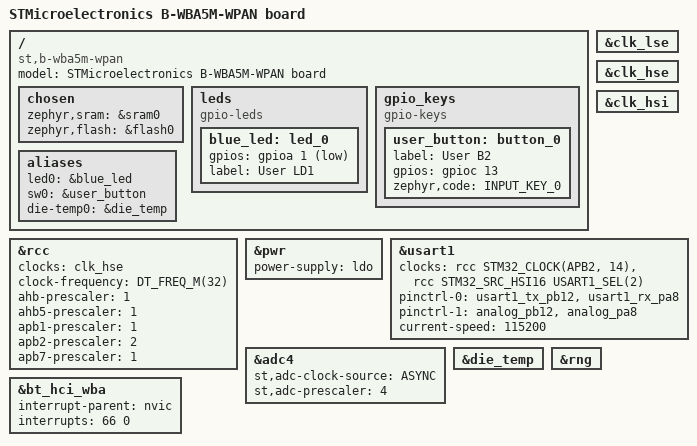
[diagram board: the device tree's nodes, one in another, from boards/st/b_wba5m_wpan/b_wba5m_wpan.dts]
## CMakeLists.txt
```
cmake_minimum_required(VERSION 3.20.0)

# App-lokale Board-Definitionen (boards/st/...) auffindbar machen
list(APPEND BOARD_ROOT ${CMAKE_CURRENT_SOURCE_DIR})

find_package(Zephyr REQUIRED HINTS $ENV{ZEPHYR_BASE})
project(ble_serial_bridge)

target_sources(app PRIVATE src/main.c)
```

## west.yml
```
# West-Manifest: pinnt Zephyr auf v4.4.2 (passend zum Zephyr SDK 1.0.x).
#
# Verwendung (T2-Topologie, diese Repo ist das Manifest-Repository):
#   west init -l <pfad-zu-diesem-repo>
#   west update
manifest:
  self:
    path: bleserial

  remotes:
    - name: zephyrproject-rtos
      url-base: https://github.com/zephyrproject-rtos

  projects:
    - name: zephyr
      remote: zephyrproject-rtos
      revision: v4.4.2
      import:
        # Nur die Module holen, die fuer STM32WB gebraucht werden
        # (mbedtls + tf-psa-crypto: PSA-Crypto fuer den Bluetooth-Host)
        name-allowlist:
          - cmsis
          - cmsis_6
          - hal_stm32
          - mbedtls
          - tf-psa-crypto
```

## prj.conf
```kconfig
# Bluetooth LE Peripheral mit Zephyr-NUS-Service (Nordic UART Service UUIDs)
CONFIG_BT=y
CONFIG_BT_PERIPHERAL=y
CONFIG_BT_MAX_CONN=1
CONFIG_BT_DEVICE_NAME="BLESerial-WB5MM"
CONFIG_BT_ZEPHYR_NUS=y

# Groessere ATT-MTU zulassen (Central muss sie aushandeln):
# 247 Byte MTU => 244 Byte Nutzdaten pro Notification
CONFIG_BT_L2CAP_TX_MTU=247
CONFIG_BT_BUF_ACL_TX_SIZE=251
CONFIG_BT_BUF_ACL_RX_SIZE=251

# Bridge-UART (LPUART1, interruptgesteuert mit Ringpuffern)
CONFIG_SERIAL=y
CONFIG_UART_INTERRUPT_DRIVEN=y
CONFIG_RING_BUFFER=y

# Status-/Diagnoseausgaben auf der ST-LINK-VCP-Konsole (USART1)
CONFIG_LOG=y
CONFIG_LOG_DEFAULT_LEVEL=3
```

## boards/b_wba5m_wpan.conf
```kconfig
# Kein Konsolen-UART auf diesem Board: USART1 gehoert der Bridge,
# daher Logging deaktivieren.
CONFIG_LOG=n
```

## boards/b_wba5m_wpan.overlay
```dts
/*
 * B-WBA5M-WPAN: USART1 als Bridge-UART verwenden.
 *
 * USART1 (PB12 = TX, PA8 = RX) ist der Host-UART der M.2-E-Key-Karte
 * (BSP "COM1") - die Karte verhaelt sich damit als transparentes
 * BLE-Serial-Modem fuer das Host-Board.
 */

/ {
	aliases {
		bridge-uart = &usart1;
	};
};

&usart1 {
	status = "okay";
	current-speed = <115200>;
};
```

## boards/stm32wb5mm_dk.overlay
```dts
/*
 * STM32WB5MM-DK: LPUART1 als Bridge-UART verwenden.
 *
 * LPUART1 liegt auf freien Pins am STMod+-Steckverbinder (CN5):
 *   PA2 = LPUART1_TX, PA3 = LPUART1_RX
 * USART1 (PB6/PB7, ST-LINK VCP) bleibt fuer Konsole/Logging frei.
 */

/ {
	aliases {
		bridge-uart = &lpuart1;
	};

	chosen {
		/*
		 * Die Board-DTS routet BT-Monitor/C2H-Debug auf LPUART1.
		 * Beides wird hier nicht genutzt - LPUART1 gehoert der Bridge.
		 */
		/delete-property/ zephyr,bt-mon-uart;
		/delete-property/ zephyr,bt-c2h-uart;
	};
};

&lpuart1 {
	status = "okay";
	current-speed = <115200>;
};
```

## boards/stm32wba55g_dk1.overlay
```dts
/*
 * STM32WBA55G-DK1: USART2 als Bridge-UART verwenden.
 *
 * USART2 liegt auf freien Pins:
 *   PB0  = USART2_TX -> ARDUINO D1, ebenso STMod+ CN12 (JP2 = ON)
 *   PA11 = USART2_RX -> ARDUINO D0, ebenso STMod+ CN12 (JP2 = ON)
 * USART1 (PB12/PA8, ST-LINK VCP) bleibt fuer Konsole/Logging frei.
 */

/ {
	aliases {
		bridge-uart = &usart2;
	};
};

&usart2 {
	status = "okay";
	current-speed = <115200>;
};
```

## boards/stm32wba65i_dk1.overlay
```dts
/*
 * STM32WBA65I-DK1: USART2 als Bridge-UART verwenden.
 *
 * USART2 liegt auf den freien Arduino-Pins:
 *   PA12 = USART2_TX -> ARDUINO D1
 *   PA11 = USART2_RX -> ARDUINO D0
 * USART1 (PB12/PA8, ST-LINK VCP) bleibt fuer Konsole/Logging frei.
 *
 * SPI1 (Arduino) nutzt ebenfalls PA12 als NSS — muss daher aus.
 *
 * Zephyr 4.4.2 Board-DTS laeuft mit HSE/2 @ 16 MHz und ahb5/2 — zu langsam
 * fuer den BLE-Link-Layer (kein sichtbares Advertising). Align mit upstream /
 * nucleo_wba65ri: 32 MHz SYSCLK, ahb5-prescaler = 1.
 */

/ {
	aliases {
		bridge-uart = &usart2;
		die-temp0 = &die_temp;
	};
};

/* Radio-taugliche Taktung (siehe Zephyr-Hauptlinie stm32wba65i_dk1.dts) */
&clk_hse {
	status = "okay";
	/delete-property/ hse-div2;
	/delete-property/ hse-trimming;
};

&rcc {
	clocks = <&clk_hse>;
	clock-frequency = <DT_FREQ_M(32)>; /* Minimum fuer Radio-Events */
	ahb-prescaler = <1>;
	ahb5-prescaler = <1>;
	apb1-prescaler = <1>;
	apb2-prescaler = <2>;
	apb7-prescaler = <1>;
};

/*
 * Die-Temperatursensor fuer die temperaturbasierte RF-Kalibrierung des
 * BLE-Link-Layers (ADC4 ist auf diesem Board bereits aktiv).
 */
&die_temp {
	status = "okay";
};

/* PA12-Konflikt mit usart2_tx vermeiden */
&spi1 {
	status = "disabled";
};

&usart2 {
	clocks = <&rcc STM32_CLOCK(APB1, 17)>,
		 <&rcc STM32_SRC_HSI16 USART2_SEL(2)>;
	pinctrl-0 = <&usart2_tx_pa12 &usart2_rx_pa11>;
	pinctrl-1 = <&analog_pa12 &analog_pa11>;
	pinctrl-names = "default", "sleep";
	current-speed = <115200>;
	status = "okay";
};

/*
 * Radio-IRQ (66) + SW-Low (HASH=61) im Devicetree, damit NUM_IRQS gross
 * genug ist (Zephyr 4.4 hat das fuer WBA65 noch nicht upstream).
 */
&bt_hci_wba {
	interrupt-parent = <&nvic>;
	interrupts = <66 0>, <61 0>;
	interrupt-names = "radio", "radio-sw-low";
};
```

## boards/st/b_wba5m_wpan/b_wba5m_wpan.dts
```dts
/*
 * Copyright (c) 2026 Protronic GmbH
 *
 * SPDX-License-Identifier: Apache-2.0
 *
 * B-WBA5M-WPAN: Bluetooth LE connectivity expansion board (M.2 E-Key)
 * with the STM32WBA5MMG module (STM32WBA55-class die, 1 MB flash,
 * HSE/LSE crystals integrated in the module).
 *
 *  - USART1: UART to the M.2 E-Key host connector (BSP "COM1",
 *    TX = PB12, RX = PA8)
 *  - User LED LD1 (blue, active low) on PA1
 *  - User button B2 (active high, pull-down) on PC13
 *  - I2C3 (PA6/PA7) with on-board motion/env sensors and EEPROM is
 *    not described here - unused by this application.
 */

/dts-v1/;
#include <st/wba/stm32wba55Xg.dtsi>
#include <st/wba/stm32wba5mmghx-pinctrl.dtsi>
#include <zephyr/dt-bindings/input/input-event-codes.h>

/ {
	model = "STMicroelectronics B-WBA5M-WPAN board";
	compatible = "st,b-wba5m-wpan";

	#address-cells = <1>;
	#size-cells = <1>;

	chosen {
		zephyr,sram = &sram0;
		zephyr,flash = &flash0;
	};

	leds: leds {
		compatible = "gpio-leds";

		blue_led: led_0 {
			gpios = <&gpioa 1 GPIO_ACTIVE_LOW>;
			label = "User LD1";
		};
	};

	gpio_keys {
		compatible = "gpio-keys";

		user_button: button_0 {
			label = "User B2";
			gpios = <&gpioc 13 (GPIO_ACTIVE_HIGH | GPIO_PULL_DOWN)>;
			zephyr,code = <INPUT_KEY_0>;
		};
	};

	aliases {
		led0 = &blue_led;
		sw0 = &user_button;
		die-temp0 = &die_temp;
	};
};

&clk_lse {
	status = "okay";
};

&clk_hse {
	status = "okay";

	/*
	 * Disable HSE trim applied by Clock Control.
	 * Board-specific init will apply trim from OTP.
	 */
	/delete-property/ hse-trimming;
};

&clk_hsi {
	status = "okay";
};

&rcc {
	clocks = <&clk_hse>;
	clock-frequency = <DT_FREQ_M(32)>; /* Lowest value to manage radio events */
	ahb-prescaler = <1>;
	ahb5-prescaler = <1>;
	apb1-prescaler = <1>;
	apb2-prescaler = <2>;
	apb7-prescaler = <1>;
};

&pwr {
	power-supply = "ldo";
};

/* UART to the M.2 E-Key host connector (BSP COM1) */
&usart1 {
	clocks = <&rcc STM32_CLOCK(APB2, 14)>,
		 <&rcc STM32_SRC_HSI16 USART1_SEL(2)>;
	pinctrl-0 = <&usart1_tx_pb12 &usart1_rx_pa8>;
	pinctrl-1 = <&analog_pb12 &analog_pa8>;
	pinctrl-names = "default", "sleep";
	current-speed = <115200>;
	status = "okay";
};

/* ADC4 + die temperature sensor: used by the BLE link layer for
 * temperature based RF calibration (internal channel only).
 */
&adc4 {
	st,adc-clock-source = "ASYNC";
	st,adc-prescaler = <4>;
	status = "okay";
};

&die_temp {
	status = "okay";
};

&rng {
	status = "okay";
};

/*
 * Make the 2.4 GHz RADIO interrupt (IRQn 66) visible in the devicetree
 * so that NUM_IRQS is computed large enough. The BLE link layer connects
 * this IRQ at runtime; Zephyr 4.4 has no dedicated radio node yet
 * (added upstream after 4.4).
 */
&bt_hci_wba {
	interrupt-parent = <&nvic>;
	interrupts = <66 0>;
	interrupt-names = "radio";
};
```

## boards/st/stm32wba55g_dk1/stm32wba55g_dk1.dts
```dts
/*
 * Copyright (c) 2026 Protronic GmbH
 *
 * SPDX-License-Identifier: Apache-2.0
 *
 * STM32WBA55G-DK1 Discovery Kit (STM32WBA55CGU6, UFQFPN48).
 *
 * Minimal board definition for this application:
 *  - USART1: ST-LINK VCP console (TX = PB12, RX = PA8)
 *  - USART2: free UART on ARDUINO D1/D0 and STMod+ CN12
 *    (TX = PB0, RX = PA11; JP2 must be ON to route UART to STMod+)
 *  - User LED LD3 (blue) on PB15
 *
 * On-board OLED, audio codec, microphones and joystick are not
 * described here - they are unused by this application.
 */

/dts-v1/;
#include <st/wba/stm32wba55Xg.dtsi>
#include <st/wba/stm32wba55cgux-pinctrl.dtsi>

/ {
	model = "STMicroelectronics STM32WBA55G-DK1 board";
	compatible = "st,stm32wba55g-dk1";

	#address-cells = <1>;
	#size-cells = <1>;

	chosen {
		zephyr,console = &usart1;
		zephyr,shell-uart = &usart1;
		zephyr,sram = &sram0;
		zephyr,flash = &flash0;
	};

	leds: leds {
		compatible = "gpio-leds";

		blue_led: led_0 {
			gpios = <&gpiob 15 GPIO_ACTIVE_HIGH>;
			label = "User LD3";
		};
	};

	aliases {
		led0 = &blue_led;
		die-temp0 = &die_temp;
	};
};

&clk_lse {
	status = "okay";
};

&clk_hse {
	status = "okay";

	/*
	 * Disable HSE trim applied by Clock Control.
	 * Board-specific init will apply trim from OTP.
	 */
	/delete-property/ hse-trimming;
};

&clk_hsi {
	status = "okay";
};

&rcc {
	clocks = <&clk_hse>;
	clock-frequency = <DT_FREQ_M(32)>; /* Lowest value to manage radio events */
	ahb-prescaler = <1>;
	ahb5-prescaler = <1>;
	apb1-prescaler = <1>;
	apb2-prescaler = <2>;
	apb7-prescaler = <1>;
};

&pwr {
	power-supply = "ldo";
};

/* ST-LINK virtual COM port */
&usart1 {
	clocks = <&rcc STM32_CLOCK(APB2, 14)>,
		 <&rcc STM32_SRC_HSI16 USART1_SEL(2)>;
	pinctrl-0 = <&usart1_tx_pb12 &usart1_rx_pa8>;
	pinctrl-1 = <&analog_pb12 &analog_pa8>;
	pinctrl-names = "default", "sleep";
	current-speed = <115200>;
	status = "okay";
};

/* Free UART: ARDUINO D1 (TX)/D0 (RX), also on STMod+ CN12 with JP2 ON */
&usart2 {
	clocks = <&rcc STM32_CLOCK(APB1, 17)>,
		 <&rcc STM32_SRC_HSI16 USART2_SEL(2)>;
	pinctrl-0 = <&usart2_tx_pb0 &usart2_rx_pa11>;
	pinctrl-1 = <&analog_pb0 &analog_pa11>;
	pinctrl-names = "default", "sleep";
	current-speed = <115200>;
	status = "okay";
};

/* ADC4 + die temperature sensor: used by the BLE link layer for
 * temperature based RF calibration (internal channel only).
 */
&adc4 {
	st,adc-clock-source = "ASYNC";
	st,adc-prescaler = <4>;
	status = "okay";
};

&die_temp {
	status = "okay";
};

&rng {
	status = "okay";
};

/*
 * Make the 2.4 GHz RADIO interrupt (IRQn 66) visible in the devicetree
 * so that NUM_IRQS is computed large enough. The BLE link layer connects
 * this IRQ at runtime; Zephyr 4.4 has no dedicated radio node yet
 * (added upstream after 4.4).
 */
&bt_hci_wba {
	interrupt-parent = <&nvic>;
	interrupts = <66 0>;
	interrupt-names = "radio";
};
```

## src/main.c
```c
/*
 * BLE <-> UART serial bridge based on the Nordic UART Service (NUS) UUIDs.
 *
 * Board: STM32WB5MM-DK
 *   - Bridge UART: LPUART1, PA2 = TX / PA3 = RX (STMod+ connector CN5),
 *     115200 8N1 (see boards/stm32wb5mm_dk.overlay)
 *   - Console/logging: USART1 via the ST-LINK virtual COM port
 *
 * Data received on the bridge UART is sent as NUS TX notifications; data
 * written to the NUS RX characteristic is forwarded to the bridge UART.
 * Both directions are decoupled with ring buffers so that neither the UART
 * ISR nor the Bluetooth stack ever blocks on the other side.
 */

#include <zephyr/kernel.h>
#include <zephyr/device.h>
#include <zephyr/devicetree.h>
#include <zephyr/drivers/uart.h>
#include <zephyr/sys/atomic.h>
#include <zephyr/sys/ring_buffer.h>
#include <zephyr/sys/util.h>
#include <zephyr/bluetooth/bluetooth.h>
#include <zephyr/bluetooth/conn.h>
#include <zephyr/bluetooth/gatt.h>
#include <zephyr/bluetooth/services/nus.h>
#include <zephyr/logging/log.h>

LOG_MODULE_REGISTER(ble_serial_bridge, LOG_LEVEL_INF);

#define UART_TO_BLE_BUF_SIZE 2048
#define BLE_TO_UART_BUF_SIZE 2048
#define UART_FIFO_CHUNK      64
#define NUS_SEND_RETRY_MS    5

/* ATT default MTU per Bluetooth Core Spec; the negotiated value arrives
 * through the att_mtu_updated callback.
 */
#define ATT_DEFAULT_MTU      23

static const struct device *const bridge_uart =
	DEVICE_DT_GET(DT_ALIAS(bridge_uart));

RING_BUF_DECLARE(uart_to_ble_rb, UART_TO_BLE_BUF_SIZE);
RING_BUF_DECLARE(ble_to_uart_rb, BLE_TO_UART_BUF_SIZE);

static atomic_t nus_subscribed;
static atomic_t uart_rx_dropped;
static atomic_t att_mtu = ATOMIC_INIT(ATT_DEFAULT_MTU);

static void ble_tx_work_handler(struct k_work *work);
static void adv_work_handler(struct k_work *work);

static K_WORK_DELAYABLE_DEFINE(ble_tx_work, ble_tx_work_handler);
static K_WORK_DEFINE(adv_work, adv_work_handler);

static const struct bt_data ad[] = {
	BT_DATA_BYTES(BT_DATA_FLAGS, (BT_LE_AD_GENERAL | BT_LE_AD_NO_BREDR)),
	BT_DATA(BT_DATA_NAME_COMPLETE, CONFIG_BT_DEVICE_NAME,
		sizeof(CONFIG_BT_DEVICE_NAME) - 1),
};

static const struct bt_data sd[] = {
	BT_DATA_BYTES(BT_DATA_UUID128_ALL, BT_UUID_NUS_SRV_VAL),
};

/* UART ISR: drain RX FIFO into the UART->BLE ring buffer, feed the TX FIFO
 * from the BLE->UART ring buffer.
 */
static void bridge_uart_isr(const struct device *dev, void *user_data)
{
	ARG_UNUSED(user_data);

	while (uart_irq_update(dev) && uart_irq_is_pending(dev)) {
		if (uart_irq_rx_ready(dev)) {
			uint8_t buf[UART_FIFO_CHUNK];
			int n = uart_fifo_read(dev, buf, sizeof(buf));

			if (n > 0) {
				uint32_t written =
					ring_buf_put(&uart_to_ble_rb, buf, n);

				if (written < (uint32_t)n) {
					atomic_add(&uart_rx_dropped,
						   n - written);
				}
				k_work_schedule(&ble_tx_work, K_NO_WAIT);
			}
		}

		if (uart_irq_tx_ready(dev)) {
			uint8_t *data;
			uint32_t len = ring_buf_get_claim(&ble_to_uart_rb,
							  &data,
							  UART_FIFO_CHUNK);

			if (len == 0) {
				uart_irq_tx_disable(dev);
			} else {
				int sent = uart_fifo_fill(dev, data, len);

				ring_buf_get_finish(&ble_to_uart_rb,
						    MAX(sent, 0));
			}
		}
	}
}

/* System workqueue: push buffered UART data out as NUS notifications,
 * chunked to the negotiated ATT MTU. Retries with a short delay when the
 * host runs out of TX buffers.
 */
static void ble_tx_work_handler(struct k_work *work)
{
	struct k_work_delayable *dwork = k_work_delayable_from_work(work);
	uint8_t *data;
	uint32_t len;

	atomic_val_t dropped = atomic_clear(&uart_rx_dropped);

	if (dropped > 0) {
		LOG_WRN("UART RX overrun, %ld bytes dropped", (long)dropped);
	}

	if (!atomic_get(&nus_subscribed)) {
		/* No subscriber: discard buffered data so stale bytes do not
		 * burst out once a client connects.
		 */
		while ((len = ring_buf_get_claim(&uart_to_ble_rb, &data,
						 UART_TO_BLE_BUF_SIZE)) > 0) {
			ring_buf_get_finish(&uart_to_ble_rb, len);
		}
		return;
	}

	uint32_t max_chunk = (uint32_t)atomic_get(&att_mtu) - 3U;

	while ((len = ring_buf_get_claim(&uart_to_ble_rb, &data,
					 max_chunk)) > 0) {
		int err = bt_nus_send(NULL, data, (uint16_t)len);

		if (err == -EAGAIN || err == -ENOMEM) {
			/* Out of buffers: keep the data, retry shortly. */
			ring_buf_get_finish(&uart_to_ble_rb, 0);
			k_work_reschedule(dwork, K_MSEC(NUS_SEND_RETRY_MS));
			return;
		}

		ring_buf_get_finish(&uart_to_ble_rb, len);

		if (err != 0 && err != -ENOTCONN) {
			LOG_WRN("bt_nus_send failed (err %d), %u bytes dropped",
				err, len);
		}
	}
}

static void adv_work_handler(struct k_work *work)
{
	ARG_UNUSED(work);

	int err = bt_le_adv_start(BT_LE_ADV_CONN_FAST_1, ad, ARRAY_SIZE(ad),
				  sd, ARRAY_SIZE(sd));

	if (err == -EALREADY) {
		return;
	} else if (err != 0) {
		LOG_ERR("Failed to start advertising (err %d)", err);
	} else {
		LOG_INF("Advertising as \"%s\"", CONFIG_BT_DEVICE_NAME);
	}
}

static void nus_notif_enabled(bool enabled, void *ctx)
{
	ARG_UNUSED(ctx);

	atomic_set(&nus_subscribed, enabled ? 1 : 0);
	LOG_INF("NUS notifications %s", enabled ? "enabled" : "disabled");

	if (enabled) {
		k_work_schedule(&ble_tx_work, K_NO_WAIT);
	}
}

static void nus_received(struct bt_conn *conn, const void *data, uint16_t len,
			 void *ctx)
{
	ARG_UNUSED(conn);
	ARG_UNUSED(ctx);

	uint32_t written = ring_buf_put(&ble_to_uart_rb, data, len);

	if (written < len) {
		LOG_WRN("UART TX overflow, %u bytes dropped", len - written);
	}
	if (written > 0) {
		uart_irq_tx_enable(bridge_uart);
	}
}

static struct bt_nus_cb nus_listener = {
	.notif_enabled = nus_notif_enabled,
	.received = nus_received,
};

static void connected(struct bt_conn *conn, uint8_t err)
{
	char addr[BT_ADDR_LE_STR_LEN];

	bt_addr_le_to_str(bt_conn_get_dst(conn), addr, sizeof(addr));

	if (err != 0) {
		LOG_WRN("Connection to %s failed (err %u)", addr, err);
		return;
	}

	/* ATT MTU starts at the default until the central negotiates more */
	atomic_set(&att_mtu, ATT_DEFAULT_MTU);
	LOG_INF("Connected: %s", addr);
}

static void disconnected(struct bt_conn *conn, uint8_t reason)
{
	char addr[BT_ADDR_LE_STR_LEN];

	bt_addr_le_to_str(bt_conn_get_dst(conn), addr, sizeof(addr));

	atomic_set(&nus_subscribed, 0);
	LOG_INF("Disconnected: %s (reason 0x%02x)", addr, reason);
}

static void recycled(void)
{
	/* Connection object is free again: resume advertising */
	k_work_submit(&adv_work);
}

BT_CONN_CB_DEFINE(conn_callbacks) = {
	.connected = connected,
	.disconnected = disconnected,
	.recycled = recycled,
};

static void att_mtu_updated(struct bt_conn *conn, uint16_t tx, uint16_t rx)
{
	ARG_UNUSED(conn);
	ARG_UNUSED(rx);

	atomic_set(&att_mtu, tx);
	LOG_INF("ATT MTU: %u (%u byte payload per notification)", tx, tx - 3);
}

static struct bt_gatt_cb gatt_callbacks = {
	.att_mtu_updated = att_mtu_updated,
};

int main(void)
{
	int err;

	if (!device_is_ready(bridge_uart)) {
		LOG_ERR("Bridge UART not ready");
		return 0;
	}

	err = bt_nus_cb_register(&nus_listener, NULL);
	if (err != 0) {
		LOG_ERR("Failed to register NUS callbacks (err %d)", err);
		return 0;
	}

	bt_gatt_cb_register(&gatt_callbacks);

	err = bt_enable(NULL);
	if (err != 0) {
		LOG_ERR("Failed to enable Bluetooth (err %d)", err);
		return 0;
	}

	err = uart_irq_callback_user_data_set(bridge_uart, bridge_uart_isr,
					      NULL);
	if (err != 0) {
		LOG_ERR("Failed to set UART callback (err %d)", err);
		return 0;
	}
	uart_irq_rx_enable(bridge_uart);

	k_work_submit(&adv_work);

	LOG_INF("BLE serial bridge ready, UART %s @ %u baud",
		bridge_uart->name,
		DT_PROP(DT_ALIAS(bridge_uart), current_speed));

	return 0;
}
```
